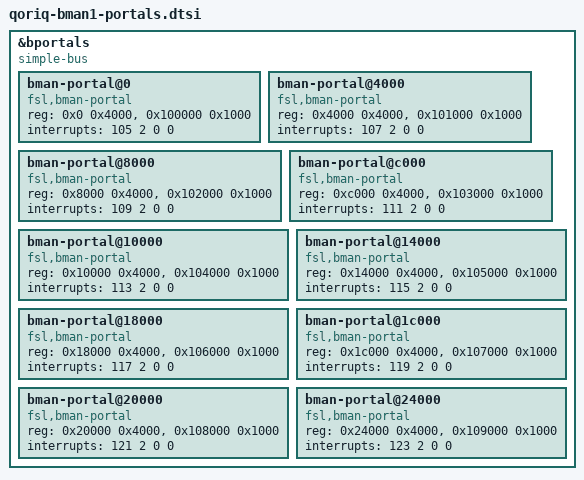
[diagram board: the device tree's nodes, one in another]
&bportals {
	#address-cells = <1>;
	#size-cells = <1>;
	compatible = "simple-bus";
	bman-portal@0 {
		compatible = "fsl,bman-portal";
		reg = <0x0 0x4000>, <0x100000 0x1000>;
		interrupts = <105 2 0 0>;
	};
	bman-portal@4000 {
		compatible = "fsl,bman-portal";
		reg = <0x4000 0x4000>, <0x101000 0x1000>;
		interrupts = <107 2 0 0>;
	};
	bman-portal@8000 {
		compatible = "fsl,bman-portal";
		reg = <0x8000 0x4000>, <0x102000 0x1000>;
		interrupts = <109 2 0 0>;
	};
	bman-portal@c000 {
		compatible = "fsl,bman-portal";
		reg = <0xc000 0x4000>, <0x103000 0x1000>;
		interrupts = <111 2 0 0>;
	};
	bman-portal@10000 {
		compatible = "fsl,bman-portal";
		reg = <0x10000 0x4000>, <0x104000 0x1000>;
		interrupts = <113 2 0 0>;
	};
	bman-portal@14000 {
		compatible = "fsl,bman-portal";
		reg = <0x14000 0x4000>, <0x105000 0x1000>;
		interrupts = <115 2 0 0>;
	};
	bman-portal@18000 {
		compatible = "fsl,bman-portal";
		reg = <0x18000 0x4000>, <0x106000 0x1000>;
		interrupts = <117 2 0 0>;
	};
	bman-portal@1c000 {
		compatible = "fsl,bman-portal";
		reg = <0x1c000 0x4000>, <0x107000 0x1000>;
		interrupts = <119 2 0 0>;
	};
	bman-portal@20000 {
		compatible = "fsl,bman-portal";
		reg = <0x20000 0x4000>, <0x108000 0x1000>;
		interrupts = <121 2 0 0>;
	};
	bman-portal@24000 {
		compatible = "fsl,bman-portal";
		reg = <0x24000 0x4000>, <0x109000 0x1000>;
		interrupts = <123 2 0 0>;
	};
};
